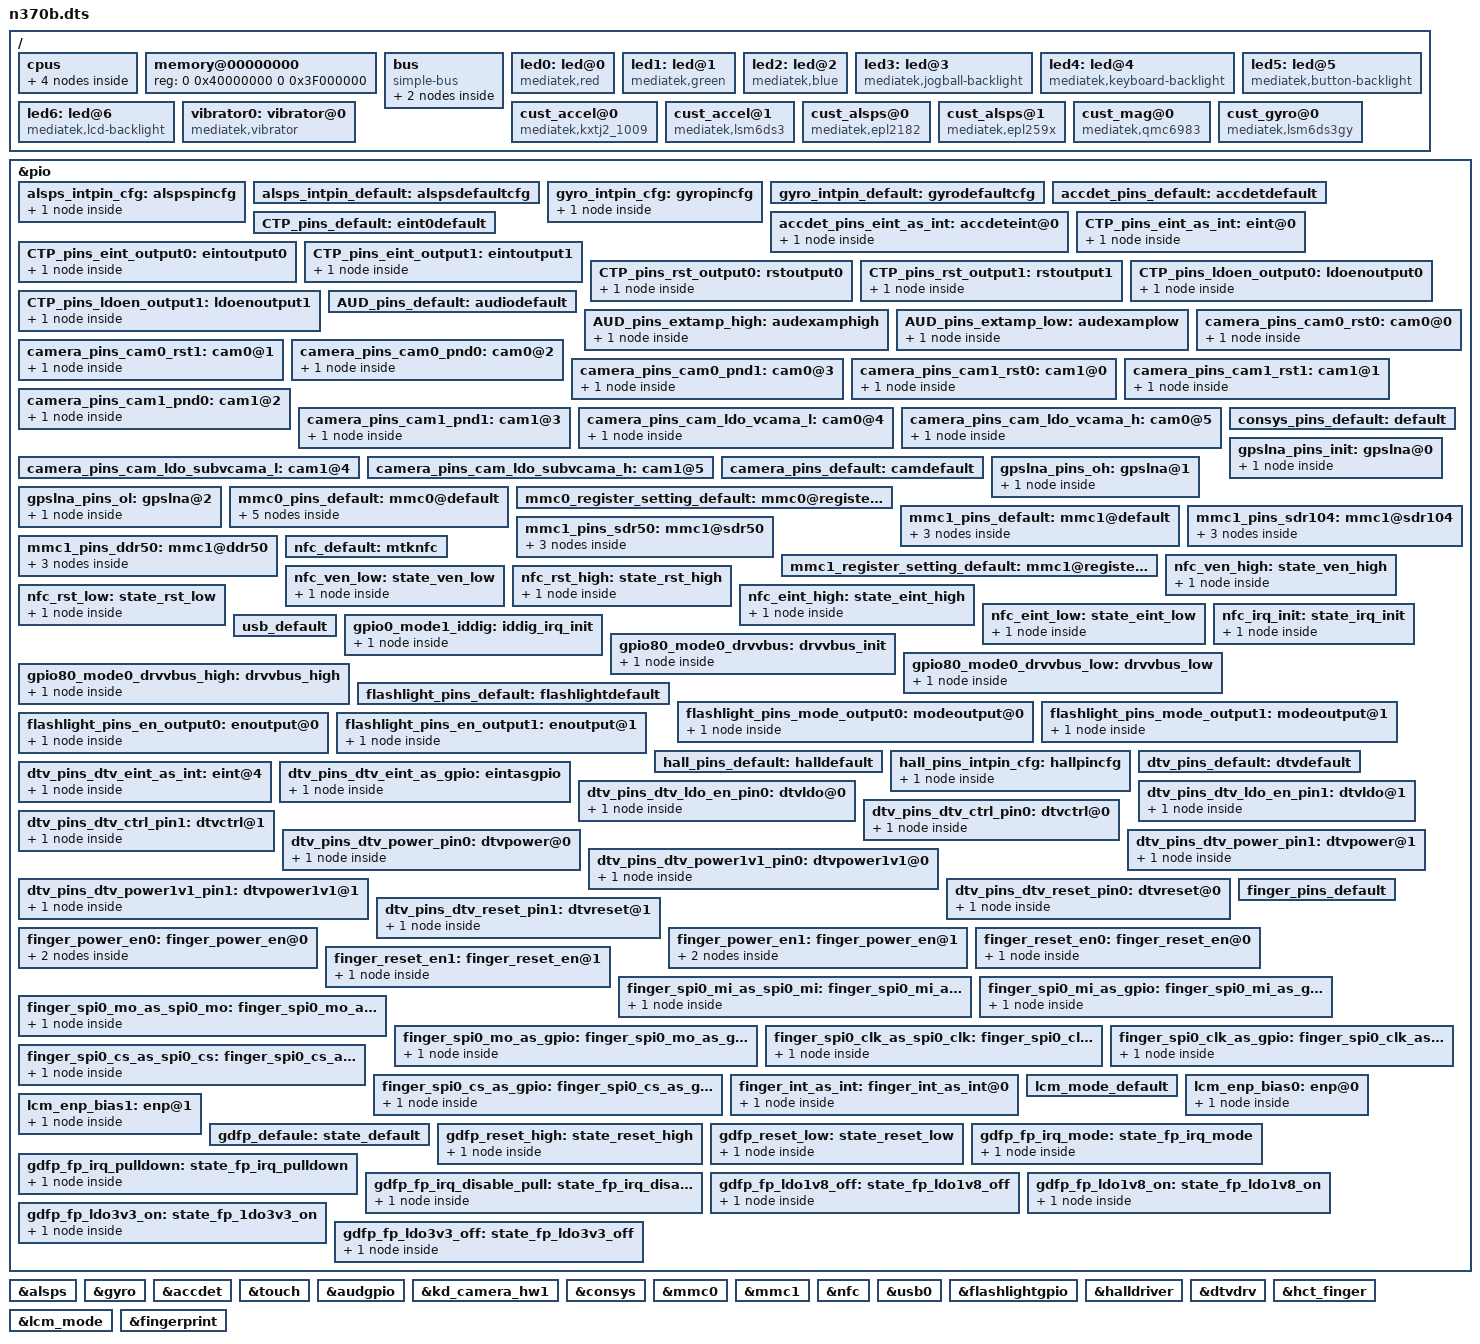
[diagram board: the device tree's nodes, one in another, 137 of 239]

/dts-v1/;

#include "mt6735m.dtsi"

/ {
	cpus {
		#address-cells = <1>;
		#size-cells = <0>;
/*		enable-method = "mediatek,mt6735-smp"; */

		cpu0: cpu@000 {
			device_type = "cpu";
			compatible = "arm,cortex-a53";
			reg = <0x000>;
			enable-method = "spin-table";
			cpu-release-addr = <0x0 0x40000200>;
			clock-frequency = <1300000000>;
		};

		cpu1: cpu@001 {
			device_type = "cpu";
			compatible = "arm,cortex-a53";
			reg = <0x001>;
			enable-method = "spin-table";
			cpu-release-addr = <0x0 0x40000200>;
			clock-frequency = <1300000000>;
		};

		cpu2: cpu@002 {
			device_type = "cpu";
			compatible = "arm,cortex-a53";
			reg = <0x002>;
			enable-method = "spin-table";
			cpu-release-addr = <0x0 0x40000200>;
			clock-frequency = <1300000000>;
		};

		cpu3: cpu@003 {
			device_type = "cpu";
			compatible = "arm,cortex-a53";
			reg = <0x003>;
			enable-method = "spin-table";
			cpu-release-addr = <0x0 0x40000200>;
			clock-frequency = <1300000000>;
		};
	};

	memory@00000000 {
		device_type = "memory";
		reg = <0 0x40000000 0 0x3F000000>;
	};

	bus {
		compatible = "simple-bus";
		#address-cells = <1>;
		#size-cells = <1>;
		ranges = <0 0 0 0xffffffff>;

		MALI@0x13040000 {
			compatible = "arm,malit720", "arm,mali-t72x", "arm,malit7xx", "arm,mali-midgard";
			reg = <0x13040000 0x4000>;
			interrupts = <0 212 0x8>, <0 211 0x8>, <0 210 0x8>;
			interrupt-names = "JOB", "MMU", "GPU";
			clock-frequency = <550000000>;
		};

		MTKFB@5e200000 {
			compatible = "mediatek,MTKFB";
			reg = <0x7F000000 0x1000000>;
		};

	};
	led0:led@0 {
		compatible = "mediatek,red";
		led_mode = <3>;
		data = <1>;
		pwm_config = <0 0 0 0 0>;
	};
	led1:led@1 {
		compatible = "mediatek,green";
		led_mode = <3>;
		data = <2>;
		pwm_config = <0 0 0 0 0>;
	};
	led2:led@2 {
		compatible = "mediatek,blue";
		led_mode = <0>;
		data = <1>;
		pwm_config = <0 0 0 0 0>;
	};
	led3:led@3 {
		compatible = "mediatek,jogball-backlight";
		led_mode = <0>;
		data = <1>;
		pwm_config = <0 0 0 0 0>;
	};
	led4:led@4 {
		compatible = "mediatek,keyboard-backlight";
		led_mode = <0>;
		data = <1>;
		pwm_config = <0 0 0 0 0>;
	};
	led5:led@5 {
		compatible = "mediatek,button-backlight";
		led_mode = <3>;
		data = <2>;
		pwm_config = <0 0 0 0 0>;
	};
	led6:led@6 {
		compatible = "mediatek,lcd-backlight";
		led_mode = <5>;
		data = <1>;
		pwm_config = <0 0 0 0 0>;
	};
	vibrator0:vibrator@0 {
		compatible = "mediatek,vibrator";
		vib_timer = <25>;
		vib_limit = <9>;
		vib_vol= <5>;
	};
 /* sensor standardization */
		cust_accel@0 {
		compatible = "mediatek,kxtj2_1009";
		i2c_num	= <2>;
		i2c_addr = <0x0f 0 0 0>;
		direction = <0>;
		power_id = <0xffff>;
		power_vol = <0>;
		firlen = <0>;
		is_batch_supported = <0>;
		};
		cust_accel@1 {
		compatible = "mediatek,lsm6ds3";
		i2c_num	= <3>;
		i2c_addr = <0x6A 0 0 0>;
		direction = <5>;
		power_id = <0xffff>;
		power_vol = <0>;
		firlen = <0>;
		is_batch_supported = <0>;
		};

		cust_alsps@0 {
		compatible = "mediatek,epl2182";
		i2c_num	= <2>;
		i2c_addr = <0x49>;
		polling_mode_ps = <0>;
		polling_mode_als = <1>;
		power_id = <0xffff>;
		power_vol = <0>;
                als_level  =  <0 400 900 1900 3125 7721 7767 12621 23062 28430 33274 47116 57694 57694 65535>;
		als_value = <0 133 304 502 1004 2005 3058 5005 8008 10010 12000 16000 20000 20000 20000 20000>;
		ps_threshold_high		=  <400>;
		ps_threshold_low		=  <300>;
		is_batch_supported_ps	= <0>;
		is_batch_supported_als	= <0>;
		};

		cust_alsps@1 {
		compatible = "mediatek,epl259x";
		i2c_num	= <2>;
		i2c_addr = <0x49>;
		polling_mode_ps = <0>;
		polling_mode_als = <1>;
		power_id = <0xffff>;
		power_vol = <0>;
                als_level  =  <0 400 900 1900 3125 7721 7767 12621 23062 28430 33274 47116 57694 57694 65535>;
                als_value  =  <0 133 304 502 1004 2005 3058 5005 8008 10010 12000 16000 20000 20000 20000 20000>;
		ps_threshold_high		=  <200>;
		ps_threshold_low		=  <100>;
		is_batch_supported_ps	= <0>;
		is_batch_supported_als	= <0>;
		};

		cust_mag@0 {
		compatible				= "mediatek,qmc6983";
		i2c_num					= <2>;
		i2c_addr				= <0x2c 0 0 0>;
		direction				= <4>;
		power_id				= <0xffff>;
		power_vol				= <0>;
		is_batch_supported			= <0>;
		};

		cust_gyro@0 {
		compatible				= "mediatek,lsm6ds3gy";
		i2c_num					= <3>;
		i2c_addr				= <0x68 0 0 0>;
		direction				= <5>;
		power_id				= <0xffff>;
		power_vol				= <0>;
		firlen					= <0>;
		is_batch_supported			= <0>;
		};
};
/* sensor gpio standization */
&pio {
	alsps_intpin_cfg: alspspincfg {

	    pins_cmd_dat {
			pins = <PINMUX_GPIO3__FUNC_GPIO3>;
			slew-rate = <0>;
			bias-pull-up = <00>;
		};
	};

	alsps_intpin_default: alspsdefaultcfg {

	};

	gyro_intpin_cfg: gyropincfg {

	    pins_cmd_dat {
			pins = <PINMUX_GPIO9__FUNC_GPIO9>;
			slew-rate = <0>;
			bias-pull-down = <00>;
		};
	};

	gyro_intpin_default: gyrodefaultcfg {

	};
};
&alsps {
	pinctrl-names = "pin_default", "pin_cfg";
	pinctrl-0 = <&alsps_intpin_default>;
	pinctrl-1 = <&alsps_intpin_cfg>;
	status = "okay";

};

&gyro {
	pinctrl-names = "pin_default", "pin_cfg";
	pinctrl-0 = <&gyro_intpin_default>;
	pinctrl-1 = <&gyro_intpin_cfg>;
	status = "okay";

};
/* sensor end */
&accdet {
		accdet-mic-vol = <7>;
		headset-mode-setting = <0x500 0x200 1 0x1F0 0x800 0x800 0x20>;
		accdet-plugout-debounce = <20>;
		/*1:ACC mode, 2:low cost without in bias, 6:low cost with in bias*/
		accdet-mic-mode = <1>;
		/*0--MD_MAX--UP_MAX--DW_MAX*/
		headset-three-key-threshold = <0 80 220 500>;
		/*0--MD_MAX--VOICE_MAX--UP_MAX--DW_MAX*/
		headset-four-key-threshold = <0 58 121 192 450>;
                pinctrl-names = "default", "state_eint_as_int";
                pinctrl-0 = <&accdet_pins_default>;
                pinctrl-1 = <&accdet_pins_eint_as_int>;
                status = "okay";
};
&pio {
accdet_pins_default: accdetdefault {
                     };   
accdet_pins_eint_as_int: accdeteint@0 {
                             pins_cmd_dat {
                                 pins = <PINMUX_GPIO6__FUNC_GPIO6>;
                                 slew-rate = <0>; 
                                 bias-disable;
                             };   
                         };   
};

&touch {
	tpd-resolution = <480 854>;
	use-tpd-button = <1>;
	tpd-key-num = <3>;
	tpd-key-local= <158 172 139 0>;
	tpd-key-dim-local = <90 2000 100 40 230 2000 100 40 370 2000 100 40 0 0 0 0>;
	tpd-max-touch-num = <5>;
	tpd-filter-enable = <0>;
	tpd-filter-pixel-density = <93>;
	tpd-filter-custom-prameters = <0 0 0 0 0 0 0 0 0 0 0 0>;
	tpd-filter-custom-speed = <0 0 0>;
	pinctrl-names = "default", "state_eint_as_int", "state_eint_output0", "state_eint_output1",
		"state_rst_output0", "state_rst_output1","state_ldoen_output0","state_ldoen_output1";
	pinctrl-0 = <&CTP_pins_default>;
	pinctrl-1 = <&CTP_pins_eint_as_int>;
	pinctrl-2 = <&CTP_pins_eint_output0>;
	pinctrl-3 = <&CTP_pins_eint_output1>;
	pinctrl-4 = <&CTP_pins_rst_output0>;
	pinctrl-5 = <&CTP_pins_rst_output1>;
	pinctrl-6 = <&CTP_pins_ldoen_output0>;
	pinctrl-7 = <&CTP_pins_ldoen_output1>;
	status = "okay";
};
&pio {
	CTP_pins_default: eint0default {
	};
	CTP_pins_eint_as_int: eint@0 {
		pins_cmd_dat {
			pins = <PINMUX_GPIO10__FUNC_GPIO10>;
			slew-rate = <0>;
			bias-disable;
		};
	};
	CTP_pins_eint_output0: eintoutput0 {
		pins_cmd_dat {
			pins = <PINMUX_GPIO10__FUNC_GPIO10>;
			slew-rate = <1>;
			output-low;
		};
	};
	CTP_pins_eint_output1: eintoutput1 {
		pins_cmd_dat {
			pins = <PINMUX_GPIO10__FUNC_GPIO10>;
			slew-rate = <1>;
			output-high;
		};
	};
	CTP_pins_rst_output0: rstoutput0 {
		pins_cmd_dat {
			pins = <PINMUX_GPIO62__FUNC_GPIO62>;
			slew-rate = <1>;
			output-low;
		};
	};
	CTP_pins_rst_output1: rstoutput1 {
		pins_cmd_dat {
			pins = <PINMUX_GPIO62__FUNC_GPIO62>;
			slew-rate = <1>;
			output-high;
		};
	};
	CTP_pins_ldoen_output0: ldoenoutput0 {
		pins_cmd_dat {
			pins = <PINMUX_GPIO9__FUNC_GPIO9>;
			slew-rate = <1>;
			output-low;
		};
	};
	CTP_pins_ldoen_output1: ldoenoutput1 {
		pins_cmd_dat {
			pins = <PINMUX_GPIO9__FUNC_GPIO9>;
			slew-rate = <1>;
			output-high;
		};
	};    
};
/* TOUCH end */
/* AUDIO GPIO standardization */
&audgpio {
	pinctrl-names = "default", "extamp-pullhigh", "extamp-pulllow";
	pinctrl-0 = <&AUD_pins_default>;
	pinctrl-1 = <&AUD_pins_extamp_high>;
	pinctrl-2 = <&AUD_pins_extamp_low>;
	status = "okay";
};
&pio {
	AUD_pins_default: audiodefault {
	};
	AUD_pins_extamp_high: audexamphigh {
		pins_cmd_dat {
			pins = <PINMUX_GPIO8__FUNC_GPIO8>;
				slew-rate = <1>;
				output-high;
		};
	};
	AUD_pins_extamp_low: audexamplow {
		pins_cmd_dat {
			pins = <PINMUX_GPIO8__FUNC_GPIO8>;
				slew-rate = <1>;
				output-low;
		};
	};
};
/* AUDIO end */
/* CAMERA GPIO standardization */
&pio {
	camera_pins_cam0_rst0: cam0@0 {
	    pins_cmd_dat {
			pins = <PINMUX_GPIO44__FUNC_GPIO44>;/*GPIO_CAMERA_CMRST_PIN*/
			slew-rate = <1>; /*direction 0:in, 1:out*/
			output-low;/*direction out used only. output_low or high*/
		};
	};
	camera_pins_cam0_rst1: cam0@1 {
	    pins_cmd_dat {
			pins = <PINMUX_GPIO44__FUNC_GPIO44>;/*GPIO_CAMERA_CMRST_PIN*/
			slew-rate = <1>;
			output-high;
		};
	};
	camera_pins_cam0_pnd0: cam0@2 {
	    pins_cmd_dat {
			pins = <PINMUX_GPIO7__FUNC_GPIO7>;/*GPIO_CAMERA_CMPDN_PIN*/
			slew-rate = <1>;
			output-low;
		};
	};
	camera_pins_cam0_pnd1: cam0@3 {
	    pins_cmd_dat {
			pins = <PINMUX_GPIO7__FUNC_GPIO7>;/*GPIO_CAMERA_CMPDN_PIN*/
			slew-rate = <1>;
			output-high;
		};
	};
	camera_pins_cam1_rst0: cam1@0 {
	    pins_cmd_dat {
			pins = <PINMUX_GPIO11__FUNC_GPIO11>;/*GPIO_CAMERA_CMRST1_PIN*/
			slew-rate = <1>; /*direction 0:in, 1:out*/
			output-low;/*direction out used only. output_low or high*/
		};
	};
	camera_pins_cam1_rst1: cam1@1 {
	    pins_cmd_dat {
			pins = <PINMUX_GPIO11__FUNC_GPIO11>;/*GPIO_CAMERA_CMRST1_PIN*/
			slew-rate = <1>;
			output-high;
		};
	};
	camera_pins_cam1_pnd0: cam1@2 {
	    pins_cmd_dat {
			pins = <PINMUX_GPIO12__FUNC_GPIO12>;/*GPIO_CAMERA_CMPDN1_PIN*/
			slew-rate = <1>;
			output-low;
		};
	};
	camera_pins_cam1_pnd1: cam1@3 {
	    pins_cmd_dat {
			pins = <PINMUX_GPIO12__FUNC_GPIO12>;/*GPIO_CAMERA_CMPDN1_PIN*/
			slew-rate = <1>;
			output-high;
		};
	};
	camera_pins_cam_ldo_vcama_l: cam0@4 {
	    pins_cmd_dat {
			pins = <PINMUX_GPIO90__FUNC_GPIO90>;/*GPIO_SPI_MOSI_PIN*/
			slew-rate = <1>;
			output-low;
		};
	};
	camera_pins_cam_ldo_vcama_h: cam0@5 {
		pins_cmd_dat {
			pins = <PINMUX_GPIO90__FUNC_GPIO90>;/*GPIO_SPI_MOSI_PIN*/
			slew-rate = <1>;
			output-high;
		};
	};
	camera_pins_cam_ldo_subvcama_l: cam1@4 {
	};
	camera_pins_cam_ldo_subvcama_h: cam1@5 {
	};
	camera_pins_default: camdefault {
	};

};

&kd_camera_hw1 {
	pinctrl-names = "default", "cam0_rst0", "cam0_rst1", "cam0_pnd0", "cam0_pnd1",
			"cam1_rst0", "cam1_rst1", "cam1_pnd0", "cam1_pnd1","cam_ldo_vcama_0", "cam_ldo_vcama_1","cam_ldo_sub_vcamd_0","cam_ldo_sub_vcamd_1";
	pinctrl-0 = <&camera_pins_default>;
	pinctrl-1 = <&camera_pins_cam0_rst0>;
	pinctrl-2 = <&camera_pins_cam0_rst1>;
	pinctrl-3 = <&camera_pins_cam0_pnd0>;
	pinctrl-4 = <&camera_pins_cam0_pnd1>;
	pinctrl-5 = <&camera_pins_cam1_rst0>;
	pinctrl-6 = <&camera_pins_cam1_rst1>;
	pinctrl-7 = <&camera_pins_cam1_pnd0>;
	pinctrl-8 = <&camera_pins_cam1_pnd1>;
	pinctrl-9 = <&camera_pins_cam_ldo_vcama_l>;
	pinctrl-10 = <&camera_pins_cam_ldo_vcama_h>;
	pinctrl-11 = <&camera_pins_cam_ldo_subvcama_l>;
	pinctrl-12 = <&camera_pins_cam_ldo_subvcama_h>;
	status = "okay";

};
/* CAMERA GPIO end */

/* CONSYS GPIO standardization */
&pio {
	consys_pins_default: default {

	};

	gpslna_pins_init: gpslna@0 {

	    pins_cmd_dat {
			pins = <PINMUX_GPIO79__FUNC_GPIO79>;
			slew-rate = <0>;
			bias-disable;
			output-low;
		};
	};

	gpslna_pins_oh: gpslna@1 {

	    pins_cmd_dat {
			pins = <PINMUX_GPIO79__FUNC_GPIO79>;
			slew-rate = <1>;
			output-high;
		};
	};

	gpslna_pins_ol: gpslna@2 {

	    pins_cmd_dat {
			pins = <PINMUX_GPIO79__FUNC_GPIO79>;
			slew-rate = <1>;
			output-low;
		};
	};

};

&consys {
	pinctrl-names = "default", "gps_lna_state_init", "gps_lna_state_oh", "gps_lna_state_ol";
	pinctrl-0 = <&consys_pins_default>;
	pinctrl-1 = <&gpslna_pins_init>;
	pinctrl-2 = <&gpslna_pins_oh>;
	pinctrl-3 = <&gpslna_pins_ol>;
	status = "okay";

};
/* CONSYS end */

/* mmc start */
&mmc0 {
		clk_src = /bits/ 8 <MSDC50_CLKSRC_400MHZ>;
		bus-width = <8>;
		max-frequency = <200000000>;
		cap-mmc-highspeed;
		msdc-sys-suspend;
		mmc-ddr-1_8v;
		mmc-hs200-1_8v;
		mmc-hs400-1_8v;
		non-removable;
		pinctl = <&mmc0_pins_default>;
		register_setting = <&mmc0_register_setting_default>;
		host_function = /bits/ 8 <MSDC_EMMC>;
		bootable;
		status = "okay";
};

&mmc1 {
		clk_src = /bits/ 8 <MSDC30_CLKSRC_200MHZ>;
		bus-width = <4>;
		max-frequency = <200000000>;
		msdc-sys-suspend;
		cap-sd-highspeed;
		sd-uhs-sdr12;
		sd-uhs-sdr25;
		sd-uhs-sdr50;
		sd-uhs-sdr104;
		sd-uhs-ddr50;
		pinctl = <&mmc1_pins_default>;
		pinctl_sdr104 = <&mmc1_pins_sdr104>;
		pinctl_sdr50 = <&mmc1_pins_sdr50>;
		pinctl_ddr50 = <&mmc1_pins_ddr50>;
		register_setting = <&mmc1_register_setting_default>;
		host_function = /bits/ 8 <MSDC_SD>;
		cd_level = /bits/ 8 <MSDC_CD_LOW>;
		cd-gpios = <&pio 106 0>;
        non-removable;
		status = "okay";
};

&pio {
	mmc0_pins_default: mmc0@default {
			pins_cmd {
				drive-strength = /bits/ 8 <2>;
			};
			pins_dat {
				drive-strength = /bits/ 8 <2>;
			};
			pins_clk {
				drive-strength = /bits/ 8 <2>;
			};
			pins_rst {
				drive-strength = /bits/ 8 <2>;
			};
			pins_ds {
				drive-strength = /bits/ 8 <2>;
			};
	};

	mmc0_register_setting_default: mmc0@register_default {
		dat0rddly      = /bits/ 8 <0>;
		dat1rddly      = /bits/ 8 <0>;
		dat2rddly      = /bits/ 8 <0>;
		dat3rddly      = /bits/ 8 <0>;
		dat4rddly      = /bits/ 8 <0>;
		dat5rddly      = /bits/ 8 <0>;
		dat6rddly      = /bits/ 8 <0>;
		dat7rddly      = /bits/ 8 <0>;
		datwrddly      = /bits/ 8 <0>;
		cmdrrddly      = /bits/ 8 <0>;
		cmdrddly       = /bits/ 8 <0>;
		cmd_edge = /bits/ 8 <MSDC_SMPL_FALLING>;
		rdata_edge = /bits/ 8 <MSDC_SMPL_FALLING>;
		wdata_edge = /bits/ 8 <MSDC_SMPL_FALLING>;

		ett-hs200-cells = <12>;
		ett-hs200-default = <OFFSET_MSDC_PATCH_BIT0	MSDC_PB0_INT_DAT_LATCH_CK_SEL 0x0
			OFFSET_MSDC_PATCH_BIT0	MSDC_PB0_CKGEN_MSDC_DLY_SEL   0x0
			OFFSET_MSDC_PATCH_BIT1	MSDC_PB1_CMD_RSP_TA_CNTR      0x1
			OFFSET_MSDC_IOCON		MSDC_IOCON_RSPL               0x0
			OFFSET_MSDC_PAD_TUNE0	MSDC_PAD_TUNE0_CMDRDLY        0x7
			OFFSET_MSDC_PAD_TUNE0	MSDC_PAD_TUNE0_CMDRRDLY       0xb
			OFFSET_MSDC_PATCH_BIT1		MSDC_PB1_WRDAT_CRCS_TA_CNTR   0x1
			OFFSET_MSDC_PAD_TUNE0	MSDC_PAD_TUNE0_DATWRDLY       0xb
			OFFSET_MSDC_IOCON			MSDC_IOCON_W_D0SPL            0x0
			OFFSET_MSDC_DAT_RDDLY0		MSDC_DAT_RDDLY0_D0            0x7
			OFFSET_MSDC_PAD_TUNE0	MSDC_PAD_TUNE0_DATRRDLY       0x9
			OFFSET_MSDC_IOCON		MSDC_IOCON_R_D_SMPL           0x0>;

		ett-hs400-cells = <8>;
		ett-hs400-default = <OFFSET_MSDC_PATCH_BIT0	MSDC_PB0_INT_DAT_LATCH_CK_SEL	0x0
			OFFSET_MSDC_PATCH_BIT0		MSDC_PB0_CKGEN_MSDC_DLY_SEL		0x0
			OFFSET_EMMC50_PAD_DS_TUNE	MSDC_EMMC50_PAD_DS_TUNE_DLY1	0x2
			OFFSET_EMMC50_PAD_DS_TUNE	MSDC_EMMC50_PAD_DS_TUNE_DLY3	0x10
			OFFSET_MSDC_PATCH_BIT1			MSDC_PB1_CMD_RSP_TA_CNTR	0x1
			OFFSET_MSDC_IOCON		MSDC_IOCON_RSPL				0x0
			OFFSET_MSDC_PAD_TUNE0			MSDC_PAD_TUNE0_CMDRDLY		0x6
			OFFSET_MSDC_PAD_TUNE0		MSDC_PAD_TUNE0_CMDRRDLY		0x6>;
	};

	mmc1_pins_default: mmc1@default {
			pins_cmd {
				drive-strength = /bits/ 8 <3>;
			};
			pins_dat {
				drive-strength = /bits/ 8 <3>;
			};
			pins_clk {
				drive-strength = /bits/ 8 <3>;
			};
	};

	mmc1_pins_sdr104: mmc1@sdr104 {
			pins_cmd {
				drive-strength = /bits/ 8 <2>;
			};
			pins_dat {
				drive-strength = /bits/ 8 <2>;
			};
			pins_clk {
				drive-strength = /bits/ 8 <3>;
			};
	};

	mmc1_pins_sdr50: mmc1@sdr50 {
			pins_cmd {
				drive-strength = /bits/ 8 <2>;
			};
			pins_dat {
				drive-strength = /bits/ 8 <2>;
			};
			pins_clk {
				drive-strength = /bits/ 8 <3>;
			};
	};

	mmc1_pins_ddr50: mmc1@ddr50 {
			pins_cmd {
				drive-strength = /bits/ 8 <2>;
			};
			pins_dat {
				drive-strength = /bits/ 8 <2>;
			};
			pins_clk {
				drive-strength = /bits/ 8 <3>;
			};
	};

	mmc1_register_setting_default: mmc1@register_default {
				dat0rddly      = /bits/ 8 <0>;
				dat1rddly      = /bits/ 8 <0>;
				dat2rddly      = /bits/ 8 <0>;
				dat3rddly      = /bits/ 8 <0>;
				datwrddly      = /bits/ 8 <0>;
				cmdrrddly      = /bits/ 8 <0>;
				cmdrddly       = /bits/ 8 <0>;
				cmd_edge = /bits/ 8 <MSDC_SMPL_FALLING>;
				rdata_edge = /bits/ 8 <MSDC_SMPL_FALLING>;
				wdata_edge = /bits/ 8 <MSDC_SMPL_FALLING>;
	};
};
/* mmc end */

/* NFC GPIO standardization */
&pio {
	nfc_default: mtknfc {

	};

	nfc_ven_high: state_ven_high {
		pins_cmd_dat {
			pins = <PINMUX_GPIO4__FUNC_GPIO4>;
			slew-rate = <1>;
			output-high;
		};
	};

	nfc_ven_low: state_ven_low {
		pins_cmd_dat {
			pins = <PINMUX_GPIO4__FUNC_GPIO4>;
			slew-rate = <1>;
			output-low;
		};
	};

	nfc_rst_high: state_rst_high {
		pins_cmd_dat {
			pins = <PINMUX_GPIO3__FUNC_GPIO3>;
			slew-rate = <1>;
			output-high;
		};
	};

	nfc_rst_low: state_rst_low {
		pins_cmd_dat {
			pins = <PINMUX_GPIO3__FUNC_GPIO3>;
			slew-rate = <1>;
			output-low;
		};
	};

	nfc_eint_high: state_eint_high {
		pins_cmd_dat {
			pins = <PINMUX_GPIO1__FUNC_GPIO1>;
			slew-rate = <1>;
			output-high;
		};
	};

	nfc_eint_low: state_eint_low {
		pins_cmd_dat {
			pins = <PINMUX_GPIO1__FUNC_GPIO1>;
			slew-rate = <1>;
			output-low;
		};
	};

	nfc_irq_init: state_irq_init {
		pins_cmd_dat {
			pins = <PINMUX_GPIO2__FUNC_GPIO2>;
			slew-rate = <0>;
			bias-pull-down = <00>;
		};
	};
};

&nfc {
	pinctrl-names = "mtknfc", "ven_high", "ven_low", "rst_high", "rst_low", "eint_high", "eint_low", "irq_init";
	pinctrl-0 = <&nfc_default>;
	pinctrl-1 = <&nfc_ven_high>;
	pinctrl-2 = <&nfc_ven_low>;
	pinctrl-3 = <&nfc_rst_high>;
	pinctrl-4 = <&nfc_rst_low>;
	pinctrl-5 = <&nfc_eint_high>;
	pinctrl-6 = <&nfc_eint_low>;
	pinctrl-7 = <&nfc_irq_init>;
	status = "okay";
};
/* NFC end */

/* USB GPIO Kernal Standardization start */
&pio {
	usb_default: usb_default {
	};

	gpio0_mode1_iddig: iddig_irq_init {
		pins_cmd_dat {
			pins = <PINMUX_GPIO0__FUNC_IDDIG>;
			slew-rate = <0>;
			bias-pull-up = <00>;
		};
	};

	gpio80_mode0_drvvbus: drvvbus_init {
		pins_cmd_dat {
			pins = <PINMUX_GPIO80__FUNC_GPIO80>;
			slew-rate = <1>;
			bias-pull-up = <00>;
		};
	};

	gpio80_mode0_drvvbus_low: drvvbus_low {
		pins_cmd_dat {
			pins = <PINMUX_GPIO80__FUNC_GPIO80>;
			slew-rate = <1>;
			output-low;
			bias-pull-down = <00>;
		};
	};

	gpio80_mode0_drvvbus_high: drvvbus_high {
		pins_cmd_dat {
			pins = <PINMUX_GPIO80__FUNC_GPIO80>;
			slew-rate = <1>;
			output-high;
			bias-pull-down = <00>;
		};
	};
};

&usb0 {
	iddig_gpio = <0 1>;
	pinctrl-names = "usb_default", "iddig_irq_init", "drvvbus_init", "drvvbus_low", "drvvbus_high";
	pinctrl-0 = <&usb_default>;
	pinctrl-1 = <&gpio0_mode1_iddig>;
	pinctrl-2 = <&gpio80_mode0_drvvbus>;
	pinctrl-3 = <&gpio80_mode0_drvvbus_low>;
	pinctrl-4 = <&gpio80_mode0_drvvbus_high>;
	status = "okay";
};
/* USB GPIO Kernal Standardization end */
/* FLASHLIGHT GPIO standardization */
&pio {
	flashlight_pins_default: flashlightdefault {
	};
    flashlight_pins_mode_output0: modeoutput@0 {
		pins_cmd_dat {
			pins = <PINMUX_GPIO42__FUNC_GPIO42>;
			slew-rate = <1>;
			output-low;
		};
	};
	flashlight_pins_mode_output1: modeoutput@1 {
		pins_cmd_dat {
			pins = <PINMUX_GPIO42__FUNC_GPIO42>;
			slew-rate = <1>;
			output-high;
		};
	};
	flashlight_pins_en_output0: enoutput@0 {
		pins_cmd_dat {
			pins = <PINMUX_GPIO43__FUNC_GPIO43>;
			slew-rate = <1>;
			output-low;
		};
	};
	flashlight_pins_en_output1: enoutput@1 {
		pins_cmd_dat {
			pins = <PINMUX_GPIO43__FUNC_GPIO43>;
			slew-rate = <1>;
			output-high;
		};
	};
};

&flashlightgpio {
	pinctrl-names = "default", "state_mode_output0", "state_mode_output1","state_en_output0", "state_en_output1";
	pinctrl-0 = <&flashlight_pins_default>;
	pinctrl-1 = <&flashlight_pins_mode_output0>;
	pinctrl-2 = <&flashlight_pins_mode_output1>;
	pinctrl-3 = <&flashlight_pins_en_output0>;
	pinctrl-4 = <&flashlight_pins_en_output1>;
	status = "okay";
};
/* FLASHLIGHT GPIO standardization  end*/

/* Hall start*/
&pio {
	hall_pins_default: halldefault {
	};
    
    hall_pins_intpin_cfg: hallpincfg {
	    pins_cmd_dat {
			pins = <PINMUX_GPIO2__FUNC_GPIO2>;
			slew-rate = <0>;
			bias-disable;
		};
	};
};
    
&halldriver {
    pinctrl-names = "default", "hall_intpin_cfg";
    pinctrl-0 = <&hall_pins_default>;
	pinctrl-1 = <&hall_pins_intpin_cfg>;    
};

/* Hall end*/
/*DTV start*/
&pio {
	dtv_pins_default: dtvdefault {
	};
    
    dtv_pins_dtv_eint_as_int: eint@4 {
		pins_cmd_dat {
			pins = <PINMUX_GPIO94__FUNC_GPIO94>;
			slew-rate = <0>;
			bias-pull-up = <00>;
		};
	};
    
    dtv_pins_dtv_eint_as_gpio: eintasgpio{
		pins_cmd_dat {
			pins = <PINMUX_GPIO94__FUNC_GPIO94>;
			slew-rate = <0>;
			bias-pull-up = <00>;
		};
	};
    
    dtv_pins_dtv_ldo_en_pin0: dtvldo@0 {
		pins_cmd_dat {
			pins = <PINMUX_GPIO88__FUNC_GPIO88>;
			slew-rate = <1>;
			output-low;
		};
	};
    
    dtv_pins_dtv_ldo_en_pin1: dtvldo@1 {
		pins_cmd_dat {
			pins = <PINMUX_GPIO88__FUNC_GPIO88>;
			slew-rate = <1>;
			output-high;
		};
	};
    
    dtv_pins_dtv_ctrl_pin0: dtvctrl@0 {
		pins_cmd_dat {
			pins = <PINMUX_GPIO63__FUNC_GPIO63>;
			slew-rate = <1>;
			output-low;
		};
	};
    
    dtv_pins_dtv_ctrl_pin1: dtvctrl@1 {
		pins_cmd_dat {
			pins = <PINMUX_GPIO63__FUNC_GPIO63>;
			slew-rate = <1>;
			output-high;
		};
	};
    
    
    dtv_pins_dtv_power_pin0: dtvpower@0 {
		pins_cmd_dat {
			pins = <PINMUX_GPIO87__FUNC_GPIO87>;
			slew-rate = <1>;
			output-low;
		};
	};
    
    dtv_pins_dtv_power_pin1: dtvpower@1 {
		pins_cmd_dat {
			pins = <PINMUX_GPIO87__FUNC_GPIO87>;
			slew-rate = <1>;
			output-high;
		};
	};    

    dtv_pins_dtv_power1v1_pin0: dtvpower1v1@0 {
		pins_cmd_dat {
			pins = <PINMUX_GPIO98__FUNC_GPIO98>;
			slew-rate = <1>;
			output-low;
		};
	};
    
    dtv_pins_dtv_power1v1_pin1: dtvpower1v1@1 {
		pins_cmd_dat {
			pins = <PINMUX_GPIO98__FUNC_GPIO98>;
			slew-rate = <1>;
			output-high;
		};
	};    

    dtv_pins_dtv_reset_pin0: dtvreset@0 {
		pins_cmd_dat {
			pins = <PINMUX_GPIO95__FUNC_GPIO95>;
			slew-rate = <1>;
			output-low;
		};
	};
    
    dtv_pins_dtv_reset_pin1: dtvreset@1 {
		pins_cmd_dat {
			pins = <PINMUX_GPIO95__FUNC_GPIO95>;
			slew-rate = <1>;
			output-high;
		};
	};    
};

&dtvdrv{
    pinctrl-names = "default", "dtv_eint_as_int", "dtv_eint_as_gpio",
                    "dtv_ldo_en_pin0","dtv_ldo_en_pin1",
                    "dtv_ctrl_pin0", "dtv_ctrl_pin1",
                    "dtv_power_pin0", "dtv_power_pin1", 
                    "dtv_power_1v1_pin0", "dtv_power_1v1_pin1", 
                    "dtv_reset_pin0", "dtv_reset_pin1";
    pinctrl-0 = <&dtv_pins_default>;
    pinctrl-1 = <&dtv_pins_dtv_eint_as_int>;
    pinctrl-2 = <&dtv_pins_dtv_eint_as_gpio>;
    pinctrl-3 = <&dtv_pins_dtv_ldo_en_pin0>;
    pinctrl-4 = <&dtv_pins_dtv_ldo_en_pin1>;
    pinctrl-5 = <&dtv_pins_dtv_ctrl_pin0>;
    pinctrl-6 = <&dtv_pins_dtv_ctrl_pin1>;
    pinctrl-7 = <&dtv_pins_dtv_power_pin0>;
    pinctrl-8 = <&dtv_pins_dtv_power_pin1>;
    pinctrl-9 = <&dtv_pins_dtv_power1v1_pin0>;
    pinctrl-10 = <&dtv_pins_dtv_power1v1_pin1>;
    pinctrl-11 = <&dtv_pins_dtv_reset_pin0>;
    pinctrl-12 = <&dtv_pins_dtv_reset_pin1>;
    status = "okay";
};
/*DTV end*/
#define __HCT_FINGERPRINT_EINT_EN_PIN_NUM__   5
#define __HCT_FINGERPRINT_EINT_PIN__    PINMUX_GPIO5__FUNC_GPIO5

#define __HCT_FINGERPRINT_RESET_PIN__    PINMUX_GPIO78__FUNC_GPIO78

&hct_finger{
	pinctrl-names = "default", "finger_power_en0","finger_power_en1","finger_reset_en0","finger_reset_en1","finger_spi0_mi_as_spi0_mi","finger_spi0_mi_as_gpio",
                          "finger_spi0_mo_as_spi0_mo","finger_spi0_mo_as_gpio","finger_spi0_clk_as_spi0_clk","finger_spi0_clk_as_gpio","finger_spi0_cs_as_spi0_cs",
                          "finger_spi0_cs_as_gpio","finger_int_as_int";
	pinctrl-0 = <&finger_pins_default>;
	pinctrl-1 = <&finger_power_en0>;
	pinctrl-2 = <&finger_power_en1>;
	pinctrl-3 = <&finger_reset_en0>;
	pinctrl-4 = <&finger_reset_en1>;
	pinctrl-5 = <&finger_spi0_mi_as_spi0_mi>;
	pinctrl-6 = <&finger_spi0_mi_as_gpio>;
	pinctrl-7 = <&finger_spi0_mo_as_spi0_mo>;
	pinctrl-8 = <&finger_spi0_mo_as_gpio>;
	pinctrl-9 = <&finger_spi0_clk_as_spi0_clk>;
	pinctrl-10= <&finger_spi0_clk_as_gpio>;
	pinctrl-11= <&finger_spi0_cs_as_spi0_cs>;
	pinctrl-12= <&finger_spi0_cs_as_gpio>;
	pinctrl-13= <&finger_int_as_int>;
};

&hct_finger {
	interrupt-parent = <&eintc>;
	interrupts = <__HCT_FINGERPRINT_EINT_EN_PIN_NUM__ IRQ_TYPE_EDGE_FALLING>;
	debounce = <__HCT_FINGERPRINT_EINT_EN_PIN_NUM__ 0>;
	status = "okay";
};

/* flashlight GPIO standardization */
&pio {
/*******************finger pin start ****************/

	finger_pins_default:finger_pins_default{
	};
	finger_power_en0:finger_power_en@0{
		    pins_cmd0_dat {
			pins = <PINMUX_GPIO87__FUNC_GPIO87>;
			slew-rate = <1>;
			output-low;
		};
		    pins_cmd1_dat {
			pins = <PINMUX_GPIO88__FUNC_GPIO88>;
			slew-rate = <1>;
			output-low;
		};
	};
	finger_power_en1:finger_power_en@1{
		    pins_cmd0_dat {
			pins = <PINMUX_GPIO87__FUNC_GPIO87>;
			slew-rate = <1>;
			output-high;
		};
		    pins_cmd1_dat {
			pins = <PINMUX_GPIO88__FUNC_GPIO88>;
			slew-rate = <1>;
			output-high;
		};
	};
	finger_reset_en0:finger_reset_en@0{
		    pins_cmd_dat {
			pins = <__HCT_FINGERPRINT_RESET_PIN__>;
			slew-rate = <1>;
			output-low;
		};
	};
	finger_reset_en1:finger_reset_en@1{
		    pins_cmd_dat {
			pins = <__HCT_FINGERPRINT_RESET_PIN__>;
			slew-rate = <1>;
			output-high;
		};
	};
	finger_spi0_mi_as_spi0_mi:finger_spi0_mi_as_spi0_mi@0{
		    pins_cmd_dat {
			pins = <PINMUX_GPIO67__FUNC_SPI_MIA>;
			slew-rate = <0>;
			
			output-low;
			
		};
	};
	finger_spi0_mi_as_gpio:finger_spi0_mi_as_gpio@0{
		    pins_cmd_dat {
			pins = <PINMUX_GPIO67__FUNC_GPIO67>;
			slew-rate = <0>;
			output-low;
			input-schmitt-enable = <0>;
		};
	};
	finger_spi0_mo_as_spi0_mo:finger_spi0_mo_as_spi0_mo@0{
		    pins_cmd_dat {
			pins = <PINMUX_GPIO68__FUNC_SPI_MOA>;
			slew-rate = <1>;
			
			output-low;
			
		};
	};
	finger_spi0_mo_as_gpio:finger_spi0_mo_as_gpio@0{
		    pins_cmd_dat {
			pins = <PINMUX_GPIO68__FUNC_GPIO68>;
			slew-rate = <1>;
			output-low;
			input-schmitt-enable = <0>;
		};
	};
	finger_spi0_clk_as_spi0_clk:finger_spi0_clk_as_spi0_clk@0{
		    pins_cmd_dat {
			pins = <PINMUX_GPIO66__FUNC_SPI_CKA>;
			slew-rate = <1>;
			
			output-low;
			
		};
	};
	finger_spi0_clk_as_gpio:finger_spi0_clk_as_gpio@0{
		    pins_cmd_dat {
			pins = <PINMUX_GPIO66__FUNC_GPIO66>;
			slew-rate = <1>;
			output-low;
			input-schmitt-enable = <0>;
		};
	};
	finger_spi0_cs_as_spi0_cs:finger_spi0_cs_as_spi0_cs@0{
		    pins_cmd_dat {
			pins = <PINMUX_GPIO65__FUNC_SPI_CSA>;
			slew-rate = <1>;
			
			output-low;
			
		};
	};
	finger_spi0_cs_as_gpio:finger_spi0_cs_as_gpio@0{
		    pins_cmd_dat {
			pins = <PINMUX_GPIO65__FUNC_GPIO65>;
			slew-rate = <1>;
			output-low;
			input-schmitt-enable = <0>;
		};
	};
	finger_int_as_int: finger_int_as_int@0{
			pins_cmd_dat {
				pins = <__HCT_FINGERPRINT_EINT_PIN__>;
				slew-rate = <0>;
				bias-pull-up = <00>;
			};
	};
};
/*******************finger pin end ****************/	
/* LCM GPIO Kernal Standardization start */
&pio {
lcm_mode_default: lcm_mode_default {
                  };   

lcm_enp_bias0: enp@0 {
                   pins_cmd_dat {
                       pins = <PINMUX_GPIO15__FUNC_GPIO15>;
                       slew-rate = <1>; 
                       output-low;
                   };   
               };   
lcm_enp_bias1: enp@1 {
                   pins_cmd_dat {
                       pins = <PINMUX_GPIO15__FUNC_GPIO15>;
                       slew-rate = <1>; 
                       output-high;
                   };   
               };   

};

&lcm_mode {
    pinctrl-names = "default", "lcm_enp_bias_l", "lcm_enp_bias_h";
    pinctrl-0 = <&lcm_mode_default>;
    pinctrl-1 = <&lcm_enp_bias0>;
    pinctrl-2 = <&lcm_enp_bias1>;
    status = "okay";
};
/* LCM GPIO Kernal Standardization end */

/*Goodix fingerprint start*/
&pio {
gdfp_defaule: state_default {
              };
gdfp_reset_high: state_reset_high{
                     pins_cmd_dat {
                         pins = <PINMUX_GPIO78__FUNC_GPIO78>;
                         slew-rate = <1>;
                         output-high;
                     };
                 };
gdfp_reset_low: state_reset_low{
                    pins_cmd_dat {
                        pins = <PINMUX_GPIO78__FUNC_GPIO78>;
                        slew-rate = <1>;
                        output-low;
                    };
                };
gdfp_fp_irq_mode: state_fp_irq_mode{
                      pins_cmd_dat {
                          pins = <PINMUX_GPIO5__FUNC_GPIO5>;
                          slew-rate = <0>;
                          bias-disable;
                      };
                  };
gdfp_fp_irq_pulldown: state_fp_irq_pulldown{
                      pins_cmd_dat {
                          pins = <PINMUX_GPIO5__FUNC_GPIO5>;
                          slew-rate = <0>;
                          bias-pull-down = <00>;
                      };
                  };
gdfp_fp_irq_disable_pull: state_fp_irq_disable_pull{
                      pins_cmd_dat {
                          pins = <PINMUX_GPIO5__FUNC_GPIO5>;
                          slew-rate = <0>;
                          bias-disable;
                      };
                  };                  
gdfp_fp_ldo1v8_off: state_fp_ldo1v8_off{
                        pins_cmd_dat {
                            pins = <PINMUX_GPIO88__FUNC_GPIO88>;
                            slew-rate = <1>;
                            output-low;
                        };
                    };
gdfp_fp_ldo1v8_on: state_fp_ldo1v8_on{
                       pins_cmd_dat {
                           pins = <PINMUX_GPIO88__FUNC_GPIO88>;
                           slew-rate = <1>;
                           output-high;
                       };
                   };
gdfp_fp_ldo3v3_on: state_fp_1do3v3_on{
                       pins_cmd_dat {
                           pins = <PINMUX_GPIO87__FUNC_GPIO87>;
                           slew-rate = <1>;
                           output-high;
                       };
                   };
gdfp_fp_ldo3v3_off: state_fp_ldo3v3_off{
                        pins_cmd_dat {
                            pins = <PINMUX_GPIO87__FUNC_GPIO87>;
                            slew-rate = <1>;
                            output-low;
                        };
                    };
};
&fingerprint {
    pinctrl-names = "default", "fp_reset_high", "fp_reset_low","fp_irq_mode", "fp_irq_pulldown", "fp_irq_disable_pull","fp_ldo1v8_off","fp_ldo1v8_on","fp_ldo3v3_on","fp_ldo3v3_off";
    pinctrl-0 = <&gdfp_defaule>;
    pinctrl-1 = <&gdfp_reset_high>;
    pinctrl-2 = <&gdfp_reset_low>;
    pinctrl-3 = <&gdfp_fp_irq_mode>;
    pinctrl-4 = <&gdfp_fp_irq_pulldown>;
    pinctrl-5 = <&gdfp_fp_irq_disable_pull>;
    pinctrl-6 = <&gdfp_fp_ldo1v8_off>;
    pinctrl-7 = <&gdfp_fp_ldo1v8_on>;
    pinctrl-8 = <&gdfp_fp_ldo3v3_on>;
    pinctrl-9 = <&gdfp_fp_ldo3v3_off>;
    /*&fingerprint*/
};
/*Goodix fingerprint end*/
